# DA1469x register map
Vendor: Dialog; Series: DA1469x; File version: 1.2
CPU: CM33 r1p0, little endian, no MPU, FPU, 3 interrupt priority bits
Registers are 32-bit, read-write, reset 0x0 unless marked. A register's access mark holds for its fields unless they carry their own. Offsets are from the block's base; [hi:lo] are bit positions; {n}, {i} and the like mark numbered series.

## CMAC — CMAC registers
Base 0x40000000
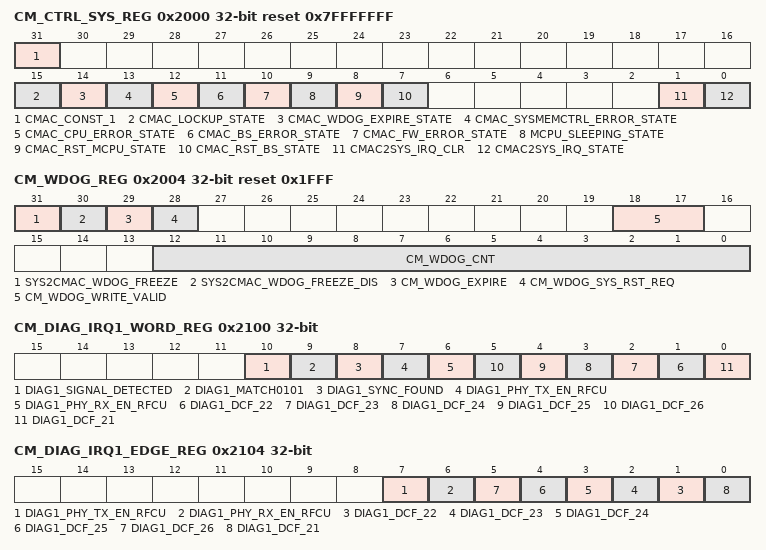
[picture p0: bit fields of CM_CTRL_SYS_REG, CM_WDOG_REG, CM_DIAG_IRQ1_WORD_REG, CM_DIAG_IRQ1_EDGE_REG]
0x2000 CM_CTRL_SYS_REG reset 0x7FFFFFFF (reset mask 0x7FFFFFFF) — CMAC and System Control Register
  [31] CMAC_CONST_1 ro — Always read as "1". Note: Creating an always non-zero register value, making easier a visual check of register when power domain is off.
  [15] CMAC_LOCKUP_STATE ro
  [14] CMAC_WDOG_EXPIRE_STATE ro
  [13] CMAC_SYSMEMCTRL_ERROR_STATE ro
  [12] CMAC_CPU_ERROR_STATE ro
  [11] CMAC_BS_ERROR_STATE ro
  [10] CMAC_FW_ERROR_STATE ro
  [9] MCPU_SLEEPING_STATE ro
  [8] CMAC_RST_MCPU_STATE ro — The state of the CMAC M0+ reset signal. Note that this reset is driven also by CLK_RADIO_REG->CMAC_SYNCH_RESET.
  [7] CMAC_RST_BS_STATE ro
  [1] CMAC2SYS_IRQ_CLR — Writing "0" will have no effect. Writing "1" will clear the CMAC2SYS_IRQ, a process that depends on the state of CMAC and the relationship of the PCLK and CMAC clocks. Reading will return "1" as long as the clearing process is pending, otherwise it will return "0".
  [0] CMAC2SYS_IRQ_STATE ro — The current state of the CMAC2SYS_IRQ signal.
0x2004 CM_WDOG_REG reset 0x1FFF (reset mask 0x7FFFFFFF) — CMAC Watch Dog Control Register
  [31] SYS2CMAC_WDOG_FREEZE ro — A read-only copy of SET_FREEZE_REG->FRZ_CMAC_WDOG value.
  [30] SYS2CMAC_WDOG_FREEZE_DIS — Setting to '1' will mask the SYS2CMAC_WDOG_FREEZE, which is provided by SET_FREEZE_REG->FRZ_CMAC_WDOG. Setting to "1" can be done only by writing at the same time CM_WDOG_WRITE_VALID with ones. The field can be only set to '1', so it can be set during the initilization and it will not change during the reloadings. It can be reseted either via power cycling the Power Domain or via the CLK_RADIO_REG->CMAC_SYNCH_RESET.
  [29] CM_WDOG_EXPIRE — This bit automatically is set to "1" as soon as CM_WDOG_CNT=0, causing CM_WDOG_CNT to start counting again from the value of "16" and also asserting CM_ERROR_REG->CM_WDOG_EXPIRE_ERR. If the SW will write CM_WDOG_EXPIRE = 0 and CM_WDOG_CNT=0, then at the next WDOG clock cycle the CM_WDOG_EXPIRE will automatically be set to to "1". If the SW will write CM_WDOG_EXPIRE = 1 and CM_WDOG_CNT=0, then at the next WDOG clock cycle the CM_WDOG_SYS_RST_REQ will automatically be set to "1". The CM_WDOG_SYS_RST_REQ will reset the system and will update the RESET_STAT_REG->CMAC_WDOGRESET_STAT. Refer also to CM_EXC_STAT_REG->EXC_WDOG_EARLY.
  [28] CM_WDOG_SYS_RST_REQ ro — Refer to CM_WDOG_EXPIRE.
  [18:17] CM_WDOG_WRITE_VALID wo — In order to allow a write of any of the remaining fields, this value must be also written simultaneously with the value "3". Reading this field will return always '0'.
  [12:0] CM_WDOG_CNT — Provides access to the counter, which counts down every 10.24 msec. FW should reload the WDOG counter by writing to CM_WDOG_REG the value (CM_WDOG_CNT | CM_WDOG_WRITE_VALID), i.e. write can be done only by writing at the same time CM_WDOG_WRITE_VALID with ones. The counter will start counting immediately after the power up of the Power Domain.
0x2100 CM_DIAG_IRQ1_WORD_REG — Diagnostic IRQ on Word1 - Word1 Register
  [10] DIAG1_SIGNAL_DETECTED ro — Refer to bit 0.
  [9] DIAG1_MATCH0101 ro — Refer to bit 0.
  [8] DIAG1_SYNC_FOUND ro — Refer to bit 0.
  [7] DIAG1_PHY_TX_EN_RFCU ro — Refer to bit 0.
  [6] DIAG1_PHY_RX_EN_RFCU ro — Refer to bit 0.
  [n-21] DIAG1_DCF_{n} ro (n=22..26) — Refer to bit 0.
  [0] DIAG1_DCF_21 ro — Same signal as the one in CM_DIAG_WORD1_REG. Refer to CM_DIAG_WORD1_REG for signal description.
0x2104 CM_DIAG_IRQ1_EDGE_REG — Diagnostic IRQ on Word1 - Edge Register
  [7] DIAG1_PHY_TX_EN_RFCU — Refer to bit 0.
  [6] DIAG1_PHY_RX_EN_RFCU — Refer to bit 0.
  [n-21] DIAG1_DCF_{n} (n=22..26) — Refer to bit 0.
  [0] DIAG1_DCF_21 — 0: The positive edge is selected to set the corresponding bit of CM_DIAG_IRQ1_STAT_REG. 1: The negative edge is selected.
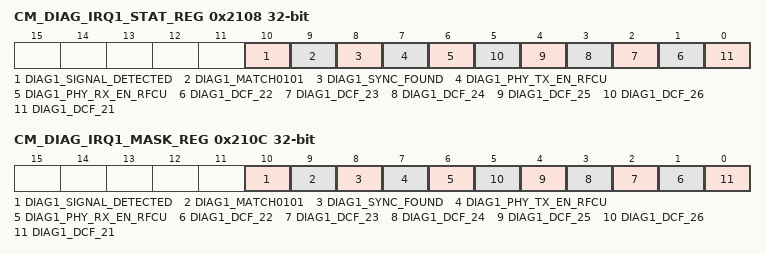
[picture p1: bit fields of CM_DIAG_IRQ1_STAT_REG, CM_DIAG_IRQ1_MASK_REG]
0x2108 CM_DIAG_IRQ1_STAT_REG — Diagnostic IRQ on Word1 - Status Register
  [10] DIAG1_SIGNAL_DETECTED — Refer to bit 0.
  [9] DIAG1_MATCH0101 — Refer to bit 0.
  [8] DIAG1_SYNC_FOUND — Refer to bit 0.
  [7] DIAG1_PHY_TX_EN_RFCU — Refer to bit 0.
  [6] DIAG1_PHY_RX_EN_RFCU — Refer to bit 0.
  [n-21] DIAG1_DCF_{n} (n=22..26) — Refer to bit 0.
  [0] DIAG1_DCF_21 — 1: the corresponding event is pending. 0: the corresponding event is not pending. Writing a '1' will clear the corresponding bit. Writing a '0' into a bit will have no effect. Use this register to detect and acknowledge the source that triggers the DIAG_IRQ.
0x210C CM_DIAG_IRQ1_MASK_REG — Diagnostic IRQ on Word1 - Mask Register
  [10] DIAG1_SIGNAL_DETECTED — Refer to bit 0.
  [9] DIAG1_MATCH0101 — Refer to bit 0.
  [8] DIAG1_SYNC_FOUND — Refer to bit 0.
  [7] DIAG1_PHY_TX_EN_RFCU — Refer to bit 0.
  [6] DIAG1_PHY_RX_EN_RFCU — Refer to bit 0.
  [n-21] DIAG1_DCF_{n} (n=22..26) — Refer to bit 0.
  [0] DIAG1_DCF_21 — 1: Raise an DIAG_IRQ when the corresponding bit of CM_DIAG_IRQ1_STAT_REG is also "1". 0: Mask the state of the corresponding bit of CM_DIAG_IRQ1_STAT_REG in order to not trigger DIAG_IRQ.
